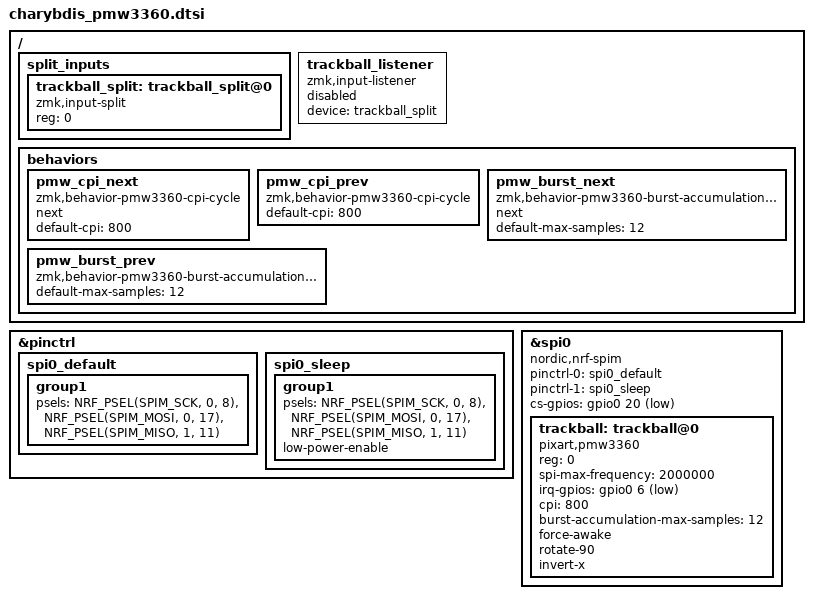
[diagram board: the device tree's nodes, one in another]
/*
 * PMW3360 trackball shield overlay for Charybdis 3x6 wireless.
 * Driver: https://github.com/mfulz/zmk-driver-pmw3360
 *
 * SPI pin assumption — mirrors 280Zo wireless mini PCB trackball connector,
 * with MISO added on D14 because PMW3360 uses 4-wire SPI (PMW3610 used 3-wire):
 *   SCK  = P0.08 (Pro Micro D0)
 *   MOSI = P0.17 (Pro Micro D2)
 *   MISO = P1.11 (Pro Micro D14) — likely requires flying wire if PCB only
 *                                   routes 3-wire SPI to the trackball connector
 *   NCS  = P0.20 (Pro Micro D3)
 *   IRQ  = P0.06 (Pro Micro D1)
 *
 * If the PCB exposes MISO on a different pad, change SPIM_MISO below.
 */

&pinctrl {
    spi0_default: spi0_default {
        group1 {
            psels = <NRF_PSEL(SPIM_SCK, 0, 8)>,
                    <NRF_PSEL(SPIM_MOSI, 0, 17)>,
                    <NRF_PSEL(SPIM_MISO, 1, 11)>;
        };
    };

    spi0_sleep: spi0_sleep {
        group1 {
            psels = <NRF_PSEL(SPIM_SCK, 0, 8)>,
                    <NRF_PSEL(SPIM_MOSI, 0, 17)>,
                    <NRF_PSEL(SPIM_MISO, 1, 11)>;
            low-power-enable;
        };
    };
};

#include <zephyr/dt-bindings/input/input-event-codes.h>

&spi0 {
    status = "okay";
    compatible = "nordic,nrf-spim";
    pinctrl-0 = <&spi0_default>;
    pinctrl-1 = <&spi0_sleep>;
    pinctrl-names = "default", "sleep";
    cs-gpios = <&gpio0 20 GPIO_ACTIVE_LOW>;

    trackball: trackball@0 {
        status = "okay";
        compatible = "pixart,pmw3360";
        reg = <0>;
        spi-max-frequency = <2000000>;
        irq-gpios = <&gpio0 6 (GPIO_ACTIVE_LOW | GPIO_PULL_UP)>;

        cpi = <800>;

        /* Accumulate up to 12 motion samples before sending — reduces BLE
           traffic, critical for wireless dongle topology (sensor lives on
           right peripheral, central polls via BLE). */
        burst-accumulation-max-samples = <12>;

        /* Keep sensor active while ZMK is in ACTIVE state; sensor falls
           back to internal rest modes when ZMK goes IDLE/SLEEP. */
        force-awake;

        /* Orientation — tune empirically after first flash. Mirrors 280Zo's
           PMW3610 transform (swap-xy + invert-x + invert-y) translated to
           mfulz rotate/invert syntax. If cursor moves wrong direction, swap
           rotate-90 ↔ rotate-270 or toggle invert-x / invert-y. */
        rotate-90;
        invert-x;
    };
};

/ {
    split_inputs {
        #address-cells = <1>;
        #size-cells = <0>;

        trackball_split: trackball_split@0 {
            compatible = "zmk,input-split";
            reg = <0>;
        };
    };

    trackball_listener: trackball_listener {
        compatible = "zmk,input-listener";
        status = "disabled"; /* enabled on central by parent overlay */
        device = <&trackball_split>;
    };

    /* Runtime tuning behaviors. Declaring the nodes here is enough to make
       behavior_pmw3360_cpi_cycle.c and behavior_pmw3360_burst_accumulation_cycle.c
       compile their bodies (each is wrapped in
       #if DT_HAS_COMPAT_STATUS_OKAY(DT_DRV_COMPAT)), which in turn provides the
       symbols pmw3360_runtime_persistence.c links against. The keymap can bind
       &pmw_cpi_next / &pmw_burst_next later without any further wiring. */
    behaviors {
        pmw_cpi_next: pmw_cpi_next {
            compatible = "zmk,behavior-pmw3360-cpi-cycle";
            #binding-cells = <0>;
            next;
            default-cpi = <800>;
        };

        pmw_cpi_prev: pmw_cpi_prev {
            compatible = "zmk,behavior-pmw3360-cpi-cycle";
            #binding-cells = <0>;
            default-cpi = <800>;
        };

        pmw_burst_next: pmw_burst_next {
            compatible = "zmk,behavior-pmw3360-burst-accumulation-cycle";
            #binding-cells = <0>;
            next;
            default-max-samples = <12>;
        };

        pmw_burst_prev: pmw_burst_prev {
            compatible = "zmk,behavior-pmw3360-burst-accumulation-cycle";
            #binding-cells = <0>;
            default-max-samples = <12>;
        };
    };
};
